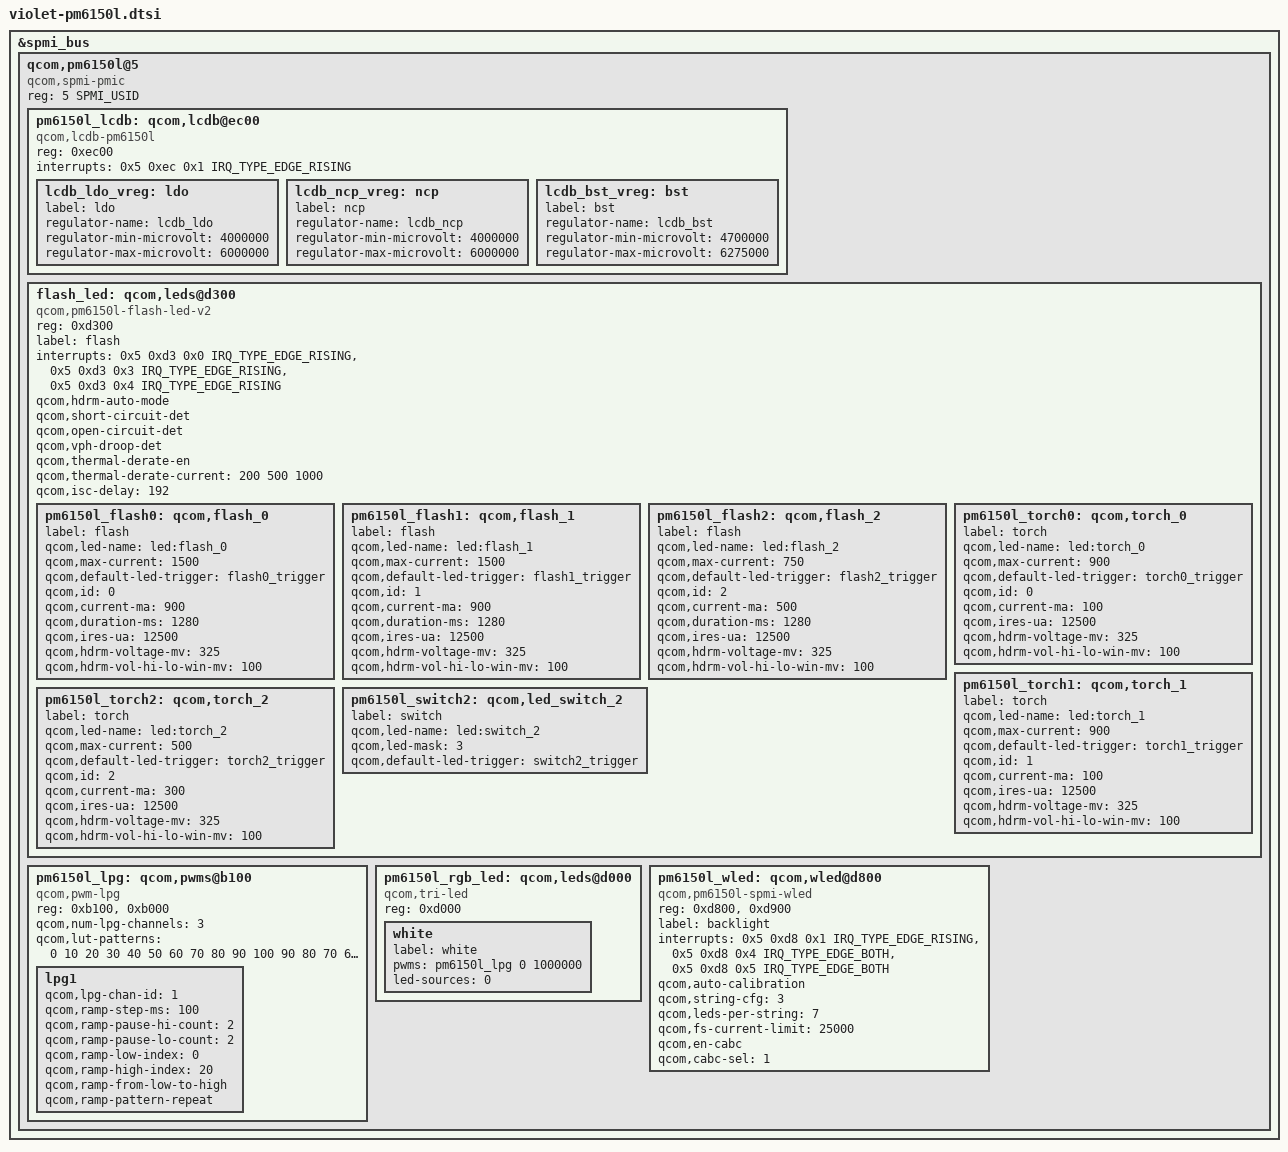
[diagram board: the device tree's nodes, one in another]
// SPDX-License-Identifier: GPL-2.0-only
/*
 * violet: the parts of pm6150l the 6.1 bring-up uses. pm6150l.dtsi is not
 * included as a whole (GPIOs, ADC, ... are not brought up yet), so
 * only SID 5 with the LCDB, the flash LEDs and WLED is described here.
 *
 * LCDB: panel lab/ibb supplies (4.14 violet: the pm6150l default without
 * qcom,voltage-step-ramp).
 *
 * WLED: panel backlight. The pm6150l.dtsi node without the flash, torch
 * and switch LEDs, with violet's 4.14 settings (fs-current-limit, CABC).
 *
 * LPG + TRI_LED: the notification LED. violet has one white LED on the
 * red current source (LPG channel 1, PWM index 0); 4.14 relabels red to
 * "white", the name the lights HAL looks for, and leaves green and blue
 * unused, so only that channel is described.
 */

#include <dt-bindings/interrupt-controller/irq.h>
#include <dt-bindings/spmi/spmi.h>

&spmi_bus {
	qcom,pm6150l@5 {
		compatible = "qcom,spmi-pmic";
		reg = <5 SPMI_USID>;
		#address-cells = <1>;
		#size-cells = <0>;

		pm6150l_lcdb: qcom,lcdb@ec00 {
			compatible = "qcom,lcdb-pm6150l";
			#address-cells = <1>;
			#size-cells = <0>;
			reg = <0xec00>;
			interrupts = <0x5 0xec 0x1 IRQ_TYPE_EDGE_RISING>;
			interrupt-names = "sc-irq";

			lcdb_ldo_vreg: ldo {
				label = "ldo";
				regulator-name = "lcdb_ldo";
				regulator-min-microvolt = <4000000>;
				regulator-max-microvolt = <6000000>;
			};

			lcdb_ncp_vreg: ncp {
				label = "ncp";
				regulator-name = "lcdb_ncp";
				regulator-min-microvolt = <4000000>;
				regulator-max-microvolt = <6000000>;
			};

			lcdb_bst_vreg: bst {
				label = "bst";
				regulator-name = "lcdb_bst";
				regulator-min-microvolt = <4700000>;
				regulator-max-microvolt = <6275000>;
			};
		};

		/*
		 * Flash LED controller: rear dual LED (flash/torch 0 and 1, switch 2
		 * drives both) and the front channel 2. Currents are violet's 4.14 values.
		 */
		flash_led: qcom,leds@d300 {
			compatible = "qcom,pm6150l-flash-led-v2";
			reg = <0xd300>;
			label = "flash";
			interrupts = <0x5 0xd3 0x0 IRQ_TYPE_EDGE_RISING>,
				     <0x5 0xd3 0x3 IRQ_TYPE_EDGE_RISING>,
				     <0x5 0xd3 0x4 IRQ_TYPE_EDGE_RISING>;
			interrupt-names = "led-fault-irq",
					  "all-ramp-down-done-irq",
					  "all-ramp-up-done-irq";
			qcom,hdrm-auto-mode;
			qcom,short-circuit-det;
			qcom,open-circuit-det;
			qcom,vph-droop-det;
			qcom,thermal-derate-en;
			qcom,thermal-derate-current = <200 500 1000>;
			qcom,isc-delay = <192>;

			pm6150l_flash0: qcom,flash_0 {
				label = "flash";
				qcom,led-name = "led:flash_0";
				qcom,max-current = <1500>;
				qcom,default-led-trigger = "flash0_trigger";
				qcom,id = <0>;
				qcom,current-ma = <900>;
				qcom,duration-ms = <1280>;
				qcom,ires-ua = <12500>;
				qcom,hdrm-voltage-mv = <325>;
				qcom,hdrm-vol-hi-lo-win-mv = <100>;
			};

			pm6150l_flash1: qcom,flash_1 {
				label = "flash";
				qcom,led-name = "led:flash_1";
				qcom,max-current = <1500>;
				qcom,default-led-trigger = "flash1_trigger";
				qcom,id = <1>;
				qcom,current-ma = <900>;
				qcom,duration-ms = <1280>;
				qcom,ires-ua = <12500>;
				qcom,hdrm-voltage-mv = <325>;
				qcom,hdrm-vol-hi-lo-win-mv = <100>;
			};

			pm6150l_flash2: qcom,flash_2 {
				label = "flash";
				qcom,led-name = "led:flash_2";
				qcom,max-current = <750>;
				qcom,default-led-trigger = "flash2_trigger";
				qcom,id = <2>;
				qcom,current-ma = <500>;
				qcom,duration-ms = <1280>;
				qcom,ires-ua = <12500>;
				qcom,hdrm-voltage-mv = <325>;
				qcom,hdrm-vol-hi-lo-win-mv = <100>;
			};

			pm6150l_torch0: qcom,torch_0 {
				label = "torch";
				qcom,led-name = "led:torch_0";
				qcom,max-current = <900>;
				qcom,default-led-trigger = "torch0_trigger";
				qcom,id = <0>;
				qcom,current-ma = <100>;
				qcom,ires-ua = <12500>;
				qcom,hdrm-voltage-mv = <325>;
				qcom,hdrm-vol-hi-lo-win-mv = <100>;
			};

			pm6150l_torch1: qcom,torch_1 {
				label = "torch";
				qcom,led-name = "led:torch_1";
				qcom,max-current = <900>;
				qcom,default-led-trigger = "torch1_trigger";
				qcom,id = <1>;
				qcom,current-ma = <100>;
				qcom,ires-ua = <12500>;
				qcom,hdrm-voltage-mv = <325>;
				qcom,hdrm-vol-hi-lo-win-mv = <100>;
			};

			pm6150l_torch2: qcom,torch_2 {
				label = "torch";
				qcom,led-name = "led:torch_2";
				qcom,max-current = <500>;
				qcom,default-led-trigger = "torch2_trigger";
				qcom,id = <2>;
				qcom,current-ma = <300>;
				qcom,ires-ua = <12500>;
				qcom,hdrm-voltage-mv = <325>;
				qcom,hdrm-vol-hi-lo-win-mv = <100>;
			};

			pm6150l_switch2: qcom,led_switch_2 {
				label = "switch";
				qcom,led-name = "led:switch_2";
				qcom,led-mask = <3>;
				qcom,default-led-trigger = "switch2_trigger";
			};
		};

		pm6150l_lpg: qcom,pwms@b100 {
			compatible = "qcom,pwm-lpg";
			reg = <0xb100>, <0xb000>;
			reg-names = "lpg-base", "lut-base";
			#pwm-cells = <2>;
			qcom,num-lpg-channels = <3>;
			qcom,lut-patterns = <0 10 20 30 40 50 60 70 80 90 100
						90 80 70 60 50 40 30 20 10 0>;

			lpg1 {
				qcom,lpg-chan-id = <1>;
				qcom,ramp-step-ms = <100>;
				qcom,ramp-pause-hi-count = <2>;
				qcom,ramp-pause-lo-count = <2>;
				qcom,ramp-low-index = <0>;
				qcom,ramp-high-index = <20>;
				qcom,ramp-from-low-to-high;
				qcom,ramp-pattern-repeat;
			};
		};

		pm6150l_rgb_led: qcom,leds@d000 {
			compatible = "qcom,tri-led";
			reg = <0xd000>;

			white {
				label = "white";
				pwms = <&pm6150l_lpg 0 1000000>;
				led-sources = <0>;
			};
		};

		pm6150l_wled: qcom,wled@d800 {
			compatible = "qcom,pm6150l-spmi-wled";
			reg = <0xd800>, <0xd900>;
			reg-names = "wled-ctrl-base", "wled-sink-base";
			label = "backlight";
			interrupts = <0x5 0xd8 0x1 IRQ_TYPE_EDGE_RISING>,
				     <0x5 0xd8 0x4 IRQ_TYPE_EDGE_BOTH>,
				     <0x5 0xd8 0x5 IRQ_TYPE_EDGE_BOTH>;
			interrupt-names = "ovp-irq", "pre-flash-irq",
					  "flash-irq";
			qcom,auto-calibration;
			/* two strings of 7 LEDs, as on 4.14 (sm6150-idp.dtsi) */
			qcom,string-cfg = <3>;
			qcom,leds-per-string = <7>;
			qcom,fs-current-limit = <25000>;
			qcom,en-cabc;
			qcom,cabc-sel = <1>;
		};
	};
};
